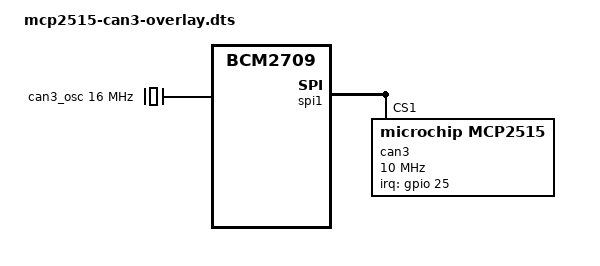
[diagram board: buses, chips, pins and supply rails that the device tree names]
/dts-v1/;
/plugin/;

/ {
    compatible = "brcm,bcm2835", "brcm,bcm2836", "brcm,bcm2708", "brcm,bcm2709";
    fragment@0 {
        target = <&spi1>;
        __overlay__ {
            status = "okay";
            spidev@1{status = "disabled";};
        };
    };

    fragment@1 {
        target = <&gpio>;
        __overlay__ {
            can3_pins: can3_pins {
                brcm,pins = <25>;
                brcm,function = <0>;
            };
        };
    };

    fragment@2 {
        target-path = "/clocks";
        __overlay__ {
            can3_osc: can3_osc {
                compatible = "fixed-clock";
                #clock-cells = <0>;
                clock-frequency  = <16000000>;
            };
        };
    };

    fragment@3 {
        target = <&spi1>;
        __overlay__ {
            #address-cells = <1>;
            #size-cells = <0>;
            can3: mcp2515@1 {
                reg = <1>;
                compatible = "microchip,mcp2515";
                pinctrl-names = "default";
                pinctrl-0 = <&can3_pins>;
                spi-max-frequency = <10000000>;
                interrupt-parent = <&gpio>;
                interrupts = <25 0x2>;
                clocks = <&can3_osc>;
            };
        };
    };
    __overrides__ {
        oscillator = <&can3_osc>,"clock-frequency:0";
        spimaxfrequency = <&can3>,"spi-max-frequency:0";
        interrupt = <&can3_pins>,"brcm,pins:0",<&can3>,"interrupts:0";
    };
};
